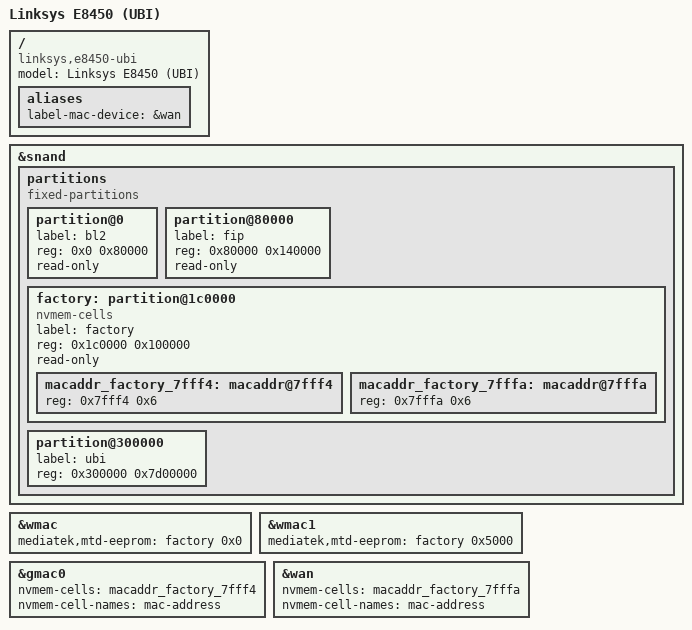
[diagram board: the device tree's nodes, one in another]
// SPDX-License-Identifier: (GPL-2.0-only OR MIT)

/dts-v1/;
#include "mt7622-linksys-e8450.dtsi"

/ {
	model = "Linksys E8450 (UBI)";
	compatible = "linksys,e8450-ubi", "mediatek,mt7622";

	aliases {
		label-mac-device = &wan;
	};
};

&snand {
	partitions {
		compatible = "fixed-partitions";
		#address-cells = <1>;
		#size-cells = <1>;

		partition@0 {
			label = "bl2";
			reg = <0x0 0x80000>;
			read-only;
		};

		partition@80000 {
			label = "fip";
			reg = <0x80000 0x140000>;
			read-only;
		};

		factory: partition@1c0000 {
			label = "factory";
			reg = <0x1c0000 0x100000>;
			read-only;
		};

		partition@300000 {
			label = "ubi";
			reg = <0x300000 0x7d00000>;
		};
	};
};

&wmac {
	mediatek,mtd-eeprom = <&factory 0x0>;
	status = "okay";
};

&wmac1 {
	mediatek,mtd-eeprom = <&factory 0x5000>;
};

&gmac0 {
	nvmem-cells = <&macaddr_factory_7fff4>;
	nvmem-cell-names = "mac-address";
};

&wan {
	nvmem-cells = <&macaddr_factory_7fffa>;
	nvmem-cell-names = "mac-address";
};

&factory {
	compatible = "nvmem-cells";
	#address-cells = <1>;
	#size-cells = <1>;

	macaddr_factory_7fff4: macaddr@7fff4 {
		reg = <0x7fff4 0x6>;
	};

	macaddr_factory_7fffa: macaddr@7fffa {
		reg = <0x7fffa 0x6>;
	};
};
